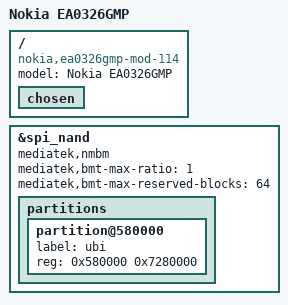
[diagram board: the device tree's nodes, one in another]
// SPDX-License-Identifier: GPL-2.0-or-later OR MIT

/dts-v1/;

#include "mt7981b-nokia-ea0326gmp.dts"

/ {
	model = "Nokia EA0326GMP";
	compatible = "nokia,ea0326gmp-mod-114", "mediatek,mt7981";
	chosen {
		/delete-property/ bootargs;
		/delete-property/ rootdisk;
	};
};

&spi_nand {
	mediatek,nmbm;
	mediatek,bmt-max-ratio = <1>;
	mediatek,bmt-max-reserved-blocks = <64>;
	partitions {
		partition@580000 {
			label = "ubi";
			reg = <0x580000 0x7280000>;
			/delete-property/ read-only;
		};
		/delete-node/ partition@780000;
		/delete-node/ partition@980000;
	};
};
